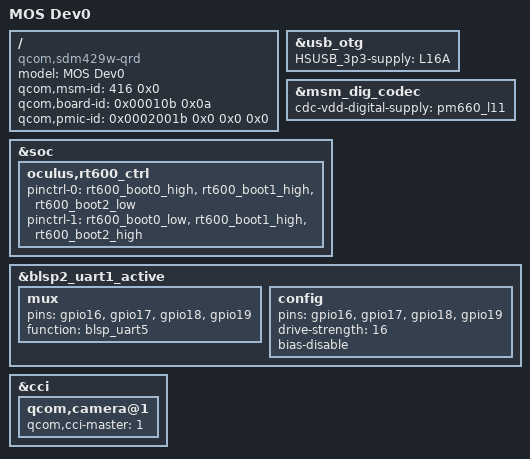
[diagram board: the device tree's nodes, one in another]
/*
 * Copyright (c) 2019, The Linux Foundation. All rights reserved.
 *
 * This program is free software; you can redistribute it and/or modify
 * it under the terms of the GNU General Public License version 2 and
 * only version 2 as published by the Free Software Foundation.
 *
 * This program is distributed in the hope that it will be useful,
 * but WITHOUT ANY WARRANTY; without even the implied warranty of
 * MERCHANTABILITY or FITNESS FOR A PARTICULAR PURPOSE.  See the
 * GNU General Public License for more details.
 */

/dts-v1/;
/plugin/;

#include "mos-common.dtsi"

/ {
	model = "MOS Dev0";
	compatible = "qcom,sdm429w-qrd", "qcom,sdm429w", "qcom,qrd";
	qcom,msm-id = <416 0x0>;
	qcom,board-id = <0x00010b 0x0a>;
	qcom,pmic-id = <0x0002001b 0x0 0x0 0x0>;
};

&usb_otg {
	HSUSB_3p3-supply = <&L16A>;
};

&msm_dig_codec {
	cdc-vdd-digital-supply = <&pm660_l11>;
};

&soc {
	oculus,rt600_ctrl {
		pinctrl-0 = <&rt600_boot0_high
				&rt600_boot1_high
				&rt600_boot2_low>;
		pinctrl-1 = <&rt600_boot0_low
				&rt600_boot1_high
				&rt600_boot2_high>;
	};
};

/* Use higher drive on Dev 0 to get around of pull up from FTDI mux */
&blsp2_uart1_active {
	mux {
		pins = "gpio16", "gpio17", "gpio18", "gpio19";
		function = "blsp_uart5";
	};

	config {
		pins = "gpio16", "gpio17", "gpio18", "gpio19";
		drive-strength = <16>;
		bias-disable;
	};
};

&cci {
	qcom,camera@1 {
		qcom,cci-master = <1>;
	};
};
